VERSION "HNPBNYYYYYYYYYYYYYYYYYYYYYYYYYYYNNNNNNNNNN/4/%%%/4/'%**4NNN///"

NS_ :

BS_:

BU_: ANYECU AD2CAN

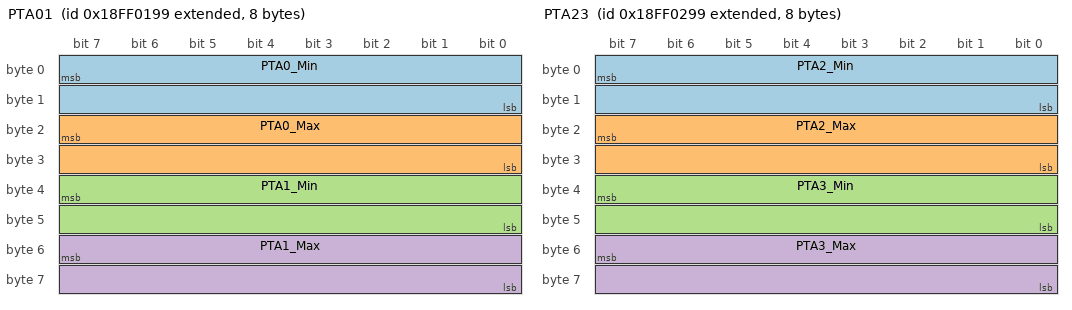
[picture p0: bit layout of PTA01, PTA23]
BO_ 2566848921 PTA01: 8 AD2CAN
 SG_ PTA0_Min : 7|16@0+ (0.0105263,0) [0|680] "V" ANYECU
 SG_ PTA0_Max : 23|16@0+ (0.0105263,0) [0|680] "V" ANYECU
 SG_ PTA1_Min : 39|16@0+ (0.0105263,0) [0|680] "V" ANYECU
 SG_ PTA1_Max : 55|16@0+ (0.0105263,0) [0|680] "V" ANYECU

BO_ 2566849177 PTA23: 8 AD2CAN
 SG_ PTA2_Min : 7|16@0+ (0.0105263,0) [0|680] "V" ANYECU
 SG_ PTA2_Max : 23|16@0+ (0.0105263,0) [0|680] "V" ANYECU
 SG_ PTA3_Min : 39|16@0+ (0.0105263,0) [0|680] "V" ANYECU
 SG_ PTA3_Max : 55|16@0+ (0.0105263,0) [0|680] "V" ANYECU

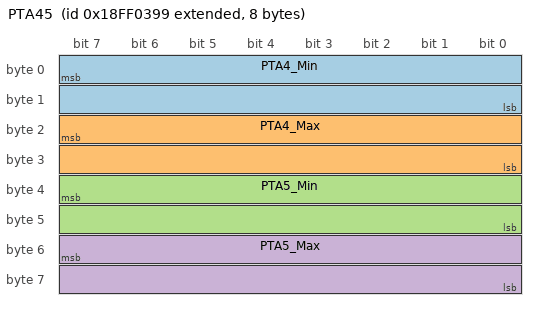
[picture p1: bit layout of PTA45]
BO_ 2566849433 PTA45: 8 AD2CAN
 SG_ PTA4_Min : 7|16@0+ (0.0105263,0) [0|680] "V" ANYECU
 SG_ PTA4_Max : 23|16@0+ (0.0105263,0) [0|680] "V" ANYECU
 SG_ PTA5_Min : 39|16@0+ (0.01154756,0) [0|680] "V" ANYECU
 SG_ PTA5_Max : 55|16@0+ (0.01154756,0) [0|680] "V" ANYECU

BA_DEF_ BO_  "GenMsgCycleTime" INT 0 65535;
BA_DEF_DEF_  "GenMsgCycleTime" 0;
BA_ "GenMsgCycleTime" BO_ 2566849433 10;
BA_ "GenMsgCycleTime" BO_ 2566849177 10;
BA_ "GenMsgCycleTime" BO_ 2566848921 10;
